# STM32F437x register map
File version: 1.0
Registers are 32-bit, read-write, reset 0x0 unless marked. A register's access mark holds for its fields unless they carry their own. Offsets are from the block's base; [hi:lo] are bit positions; {n}, {i} and the like mark numbered series; 'fields as' and 'values as' point back to an identical list.

## OTG_FS_PWRCLK — USB on the go full speed
Base 0x50000E00
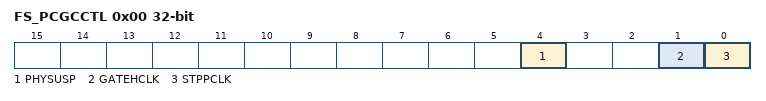
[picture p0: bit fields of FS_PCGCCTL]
0x00 FS_PCGCCTL — OTG_FS power and clock gating control register (OTG_FS_PCGCCTL)
  [4] PHYSUSP — PHY Suspended
  [1] GATEHCLK
  [0] STPPCLK — Stop PHY clock

## NVIC — Nested Vectored Interrupt Controller
Base 0xE000E000
0x04 ICTR ro — Interrupt Controller Type Register
  [3:0] INTLINESNUM — Total number of interrupt lines in groups
{0x100+4i} ISER{i} (i=0..2) — Interrupt Set-Enable Register
  [31:0] SETENA
{0x180+4i} ICER{i} (i=0..2) — Interrupt Clear-Enable Register
  [31:0] CLRENA
{0x200+4i} ISPR{i} (i=0..2) — Interrupt Set-Pending Register
  [31:0] SETPEND
{0x280+4i} ICPR{i} (i=0..2) — Interrupt Clear-Pending Register
  [31:0] CLRPEND
{0x300+4i} IABR{i} ro (i=0..2) — Interrupt Active Bit Register
  [31:0] ACTIVE
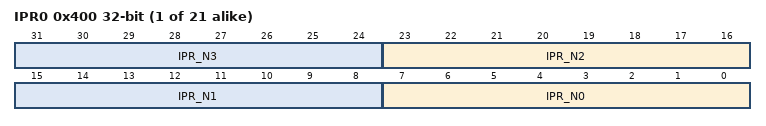
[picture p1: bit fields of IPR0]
{0x400+4i} IPR{i} (i=0..20) — Interrupt Priority Register
  [8n+7:8n] IPR_N{n} (n=0..3)
0xF00 STIR wo — Software Triggered Interrupt Register
  [8:0] INTID — interrupt to be triggered

## FLASH
Base 0x40023C00
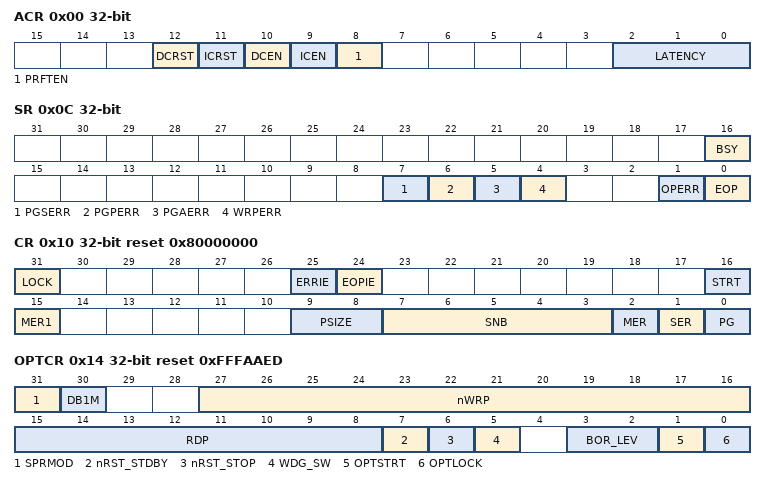
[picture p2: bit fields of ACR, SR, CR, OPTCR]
0x00 ACR access per field — Flash access control register
  [12] DCRST rw — Data cache reset
  [11] ICRST wo — Instruction cache reset
  [10] DCEN rw — Data cache enable
  [9] ICEN rw — Instruction cache enable
  [8] PRFTEN rw — Prefetch enable
  [2:0] LATENCY rw
0x04 KEYR wo — Flash key register
  [31:0] KEY — FPEC key
0x08 OPTKEYR wo — Flash option key register
  [31:0] OPTKEY — Option byte key
0x0C SR access per field — Status register
  [16] BSY ro — Busy
  [7] PGSERR rw — Programming sequence error
  [6] PGPERR rw — Programming parallelism error
  [5] PGAERR rw — Programming alignment error
  [4] WRPERR rw — Write protection error
  [1] OPERR rw — Operation error
  [0] EOP rw — End of operation
0x10 CR reset 0x80000000 — Control register
  [31] LOCK
  [25] ERRIE — Error interrupt enable
  [24] EOPIE — End of operation interrupt enable
  [16] STRT — Start
  [15] MER1 — Mass Erase of sectors 12 to 23
  [9:8] PSIZE — Program size
  [7:3] SNB — Sector number
  [2] MER — Mass Erase of sectors 0 to 11
  [1] SER — Sector Erase
  [0] PG — Programming
0x14 OPTCR reset 0xFFFAAED — Flash option control register
  [31] SPRMOD — Selection of protection mode for nWPRi bits
  [30] DB1M — Dual-bank on 1 Mbyte Flash memory devices
  [27:16] nWRP — Not write protect
  [15:8] RDP — Read protect
  [7] nRST_STDBY — nRST_STDBY User option bytes
  [6] nRST_STOP — nRST_STOP User option bytes
  [5] WDG_SW — WDG_SW User option bytes
  [3:2] BOR_LEV — BOR reset Level
  [1] OPTSTRT — Option start
  [0] OPTLOCK — Option lock
0x18 OPTCR1 reset 0xFFF0000 — Flash option control register 1
  [27:16] nWRP — Not write protect

## EXTI — External interrupt/event controller
Base 0x40013C00
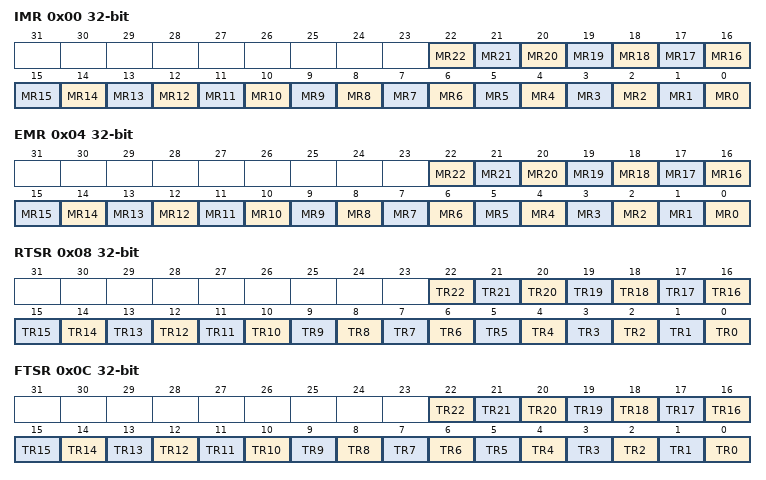
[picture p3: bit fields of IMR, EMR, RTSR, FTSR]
0x00 IMR — Interrupt mask register (EXTI_IMR)
  [n] MR{n} (n=0..22) — Interrupt Mask on line {n}
0x04 EMR — Event mask register (EXTI_EMR)
  [n] MR{n} (n=0..22) — Event Mask on line {n}
0x08 RTSR — Rising Trigger selection register (EXTI_RTSR)
  [n] TR{n} (n=0..22) — Rising trigger event configuration of line {n}
0x0C FTSR — Falling Trigger selection register (EXTI_FTSR)
  [n] TR{n} (n=0..22) — Falling trigger event configuration of line {n}
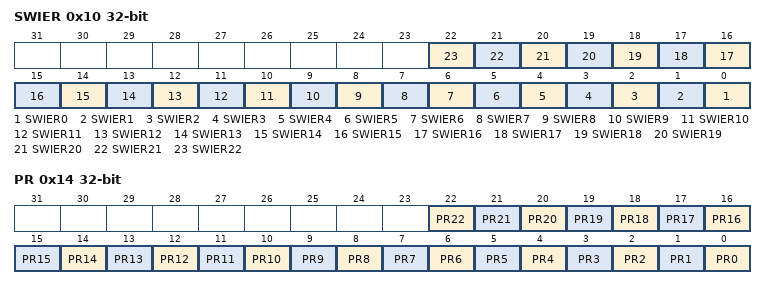
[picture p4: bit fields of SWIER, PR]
0x10 SWIER — Software interrupt event register (EXTI_SWIER)
  [n] SWIER{n} (n=0..22) — Software Interrupt on line {n}
0x14 PR — Pending register (EXTI_PR)
  [n] PR{n} (n=0..22) — Pending bit {n}

## OTG_HS_PWRCLK — USB on the go high speed
Base 0x40040E00
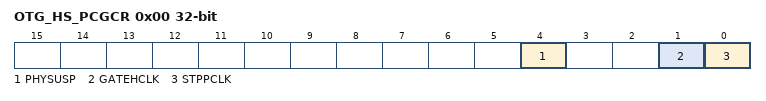
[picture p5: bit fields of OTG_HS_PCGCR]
0x00 OTG_HS_PCGCR — Power and clock gating control register
  [4] PHYSUSP — PHY suspended
  [1] GATEHCLK
  [0] STPPCLK — Stop PHY clock

## FMC — Flexible memory controller
Base 0xA0000000
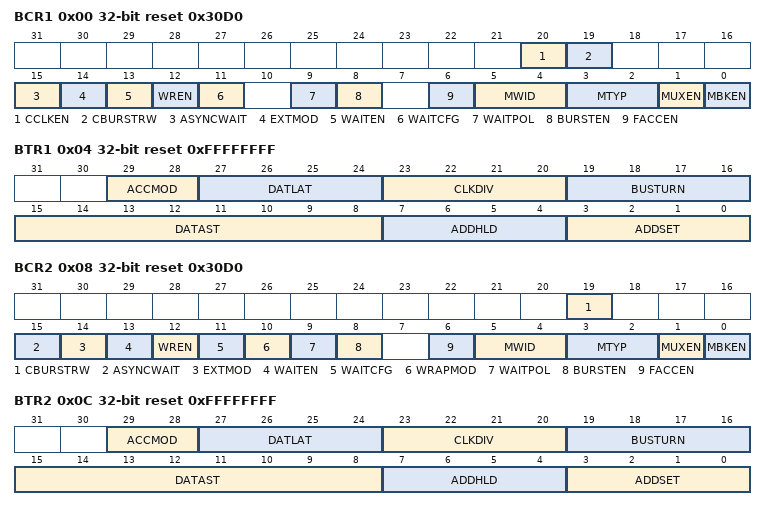
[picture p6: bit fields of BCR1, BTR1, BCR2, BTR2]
0x00 BCR1 reset 0x30D0 — SRAM/NOR-Flash chip-select control register 1
  [20] CCLKEN, [19] CBURSTRW, [15] ASYNCWAIT, [14] EXTMOD, [13] WAITEN, [12] WREN, [11] WAITCFG, [9] WAITPOL, [8] BURSTEN, [6] FACCEN, [5:4] MWID, [3:2] MTYP, [1] MUXEN, [0] MBKEN
0x04 BTR1 reset 0xFFFFFFFF — SRAM/NOR-Flash chip-select timing register 1
  [29:28] ACCMOD, [27:24] DATLAT, [23:20] CLKDIV, [19:16] BUSTURN, [15:8] DATAST, [7:4] ADDHLD, [3:0] ADDSET
0x08 BCR2 reset 0x30D0 — SRAM/NOR-Flash chip-select control register 2
  [19] CBURSTRW, [15] ASYNCWAIT, [14] EXTMOD, [13] WAITEN, [12] WREN, [11] WAITCFG, [10] WRAPMOD, [9] WAITPOL, [8] BURSTEN, [6] FACCEN, [5:4] MWID, [3:2] MTYP, [1] MUXEN, [0] MBKEN
0x0C BTR2 reset 0xFFFFFFFF — SRAM/NOR-Flash chip-select timing register 2
  fields as BTR1
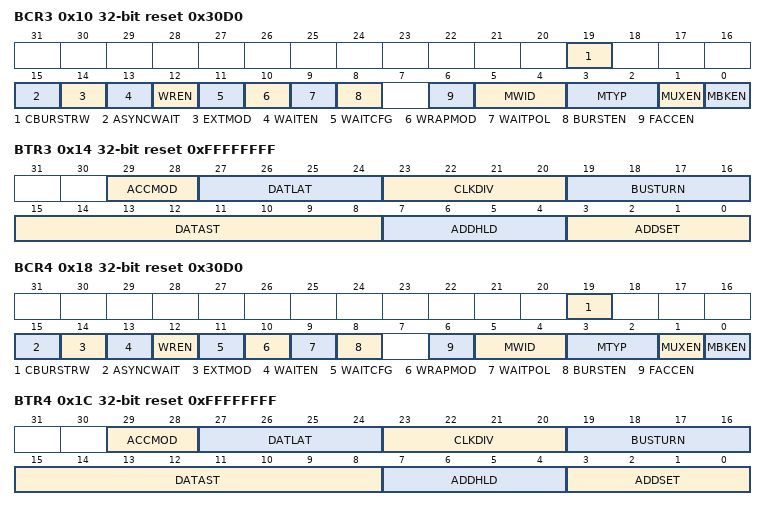
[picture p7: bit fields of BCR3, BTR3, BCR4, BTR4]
0x10 BCR3 reset 0x30D0 — SRAM/NOR-Flash chip-select control register 3
  fields as BCR2
0x14 BTR3 reset 0xFFFFFFFF — SRAM/NOR-Flash chip-select timing register 3
  fields as BTR1
0x18 BCR4 reset 0x30D0 — SRAM/NOR-Flash chip-select control register 4
  fields as BCR2
0x1C BTR4 reset 0xFFFFFFFF — SRAM/NOR-Flash chip-select timing register 4
  fields as BTR1
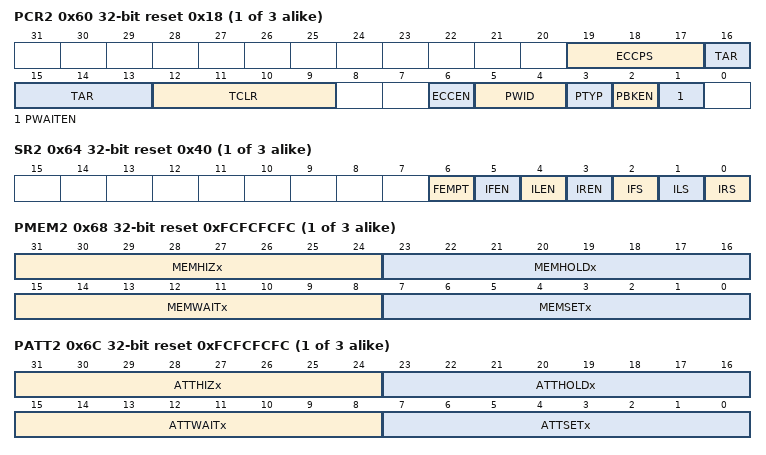
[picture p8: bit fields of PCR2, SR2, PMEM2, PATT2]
{0x20+0x20*i} PCR{i} reset 0x18 (i=2..4) — PC Card/NAND Flash control register {i}
  [19:17] ECCPS, [16:13] TAR, [12:9] TCLR, [6] ECCEN, [5:4] PWID, [3] PTYP, [2] PBKEN, [1] PWAITEN
{0x24+0x20*i} SR{i} access per field reset 0x40 (i=2..4) — FIFO status and interrupt register {i}
  [6] FEMPT ro, [5] IFEN rw, [4] ILEN rw, [3] IREN rw, [2] IFS rw, [1] ILS rw, [0] IRS rw
{0x28+0x20*i} PMEM{i} reset 0xFCFCFCFC (i=2..4) — Common memory space timing register {i}
  [31:24] MEMHIZx, [23:16] MEMHOLDx, [15:8] MEMWAITx, [7:0] MEMSETx
{0x2C+0x20*i} PATT{i} reset 0xFCFCFCFC (i=2..4) — Attribute memory space timing register {i}
  [31:24] ATTHIZx, [23:16] ATTHOLDx, [15:8] ATTWAITx, [7:0] ATTSETx
0x74 ECCR2 ro — ECC result register 2
  [31:0] ECCx
0x94 ECCR3 ro — ECC result register 3
  [31:0] ECCx
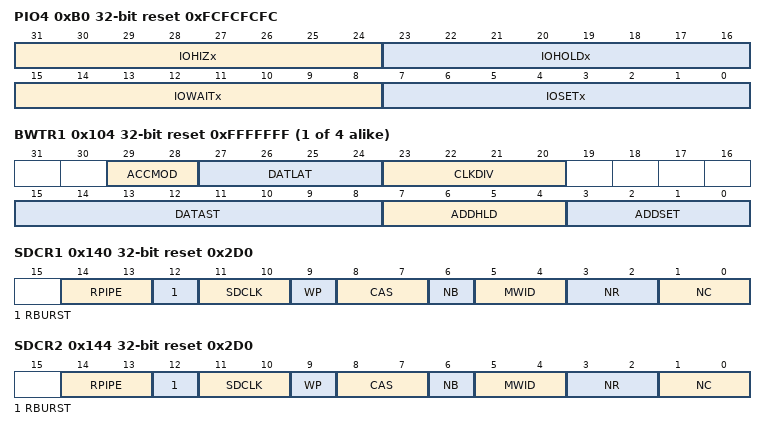
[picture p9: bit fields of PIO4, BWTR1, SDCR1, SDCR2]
0xB0 PIO4 reset 0xFCFCFCFC — I/O space timing register 4
  [31:24] IOHIZx, [23:16] IOHOLDx, [15:8] IOWAITx, [7:0] IOSETx
{0xFC+8i} BWTR{i} reset 0xFFFFFFF (i=1..4) — SRAM/NOR-Flash write timing registers {i}
  [29:28] ACCMOD, [27:24] DATLAT, [23:20] CLKDIV, [15:8] DATAST, [7:4] ADDHLD, [3:0] ADDSET
0x140 SDCR1 reset 0x2D0 — SDRAM Control Register 1
  [14:13] RPIPE — Read pipe
  [12] RBURST — Burst read
  [11:10] SDCLK — SDRAM clock configuration
  [9] WP — Write protection
  [8:7] CAS — CAS latency
  [6] NB — Number of internal banks
  [5:4] MWID — Memory data bus width
  [3:2] NR — Number of row address bits
  [1:0] NC — Number of column address bits
0x144 SDCR2 reset 0x2D0 — SDRAM Control Register 2
  fields as SDCR1
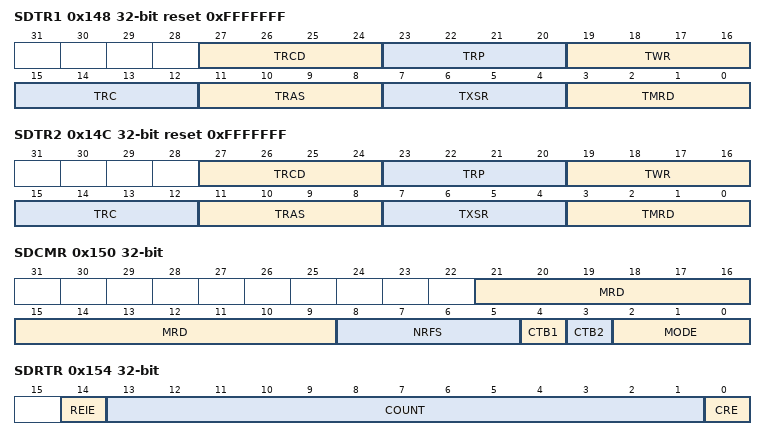
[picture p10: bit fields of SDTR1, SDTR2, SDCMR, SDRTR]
0x148 SDTR1 reset 0xFFFFFFF — SDRAM Timing register 1
  [27:24] TRCD — Row to column delay
  [23:20] TRP — Row precharge delay
  [19:16] TWR — Recovery delay
  [15:12] TRC — Row cycle delay
  [11:8] TRAS — Self refresh time
  [7:4] TXSR — Exit self-refresh delay
  [3:0] TMRD — Load Mode Register to Active
0x14C SDTR2 reset 0xFFFFFFF — SDRAM Timing register 2
  fields as SDTR1
0x150 SDCMR access per field — SDRAM Command Mode register
  [21:9] MRD rw — Mode Register definition
  [8:5] NRFS rw — Number of Auto-refresh
  [4] CTB1 wo — Command target bank 1
  [3] CTB2 wo — Command target bank 2
  [2:0] MODE wo — Command mode
0x154 SDRTR access per field — SDRAM Refresh Timer register
  [14] REIE rw — RES Interrupt Enable
  [13:1] COUNT rw — Refresh Timer Count
  [0] CRE wo — Clear Refresh error flag
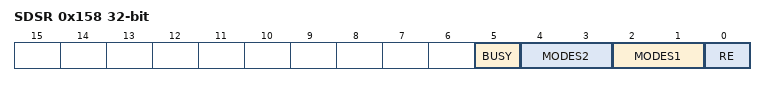
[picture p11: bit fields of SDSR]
0x158 SDSR ro — SDRAM Status register
  [5] BUSY — Busy status
  [4:3] MODES2 — Status Mode for Bank 2
  [2:1] MODES1 — Status Mode for Bank 1
  [0] RE — Refresh error flag
